AUTOSAR XML (schema 00046)
package /ComponentTypes
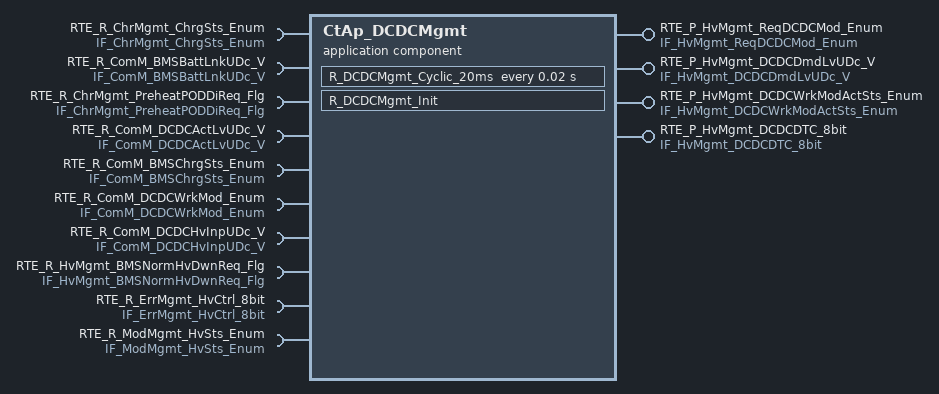
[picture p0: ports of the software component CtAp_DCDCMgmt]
  application sw component type CtAp_DCDCMgmt
    4 x provide port:
      RTE_P_HvMgmt_ReqDCDCMod_Enum: nonqueued-sender-com-spec{data-element=tec_HvMgmt_ReqDCDCMod_Enum, init-value=0}, provided-interface=IF_HvMgmt_ReqDCDCMod_Enum
      RTE_P_HvMgmt_DCDCDmdLvUDc_V: nonqueued-sender-com-spec{data-element=tec_HvMgmt_DCDCDmdLvUDc_V, init-value=0}, provided-interface=IF_HvMgmt_DCDCDmdLvUDc_V
      RTE_P_HvMgmt_DCDCWrkModActSts_Enum: nonqueued-sender-com-spec{data-element=tec_HvMgmt_DCDCWrkModActSts_Enum, init-value=0}, provided-interface=IF_HvMgmt_DCDCWrkModActSts_Enum
      RTE_P_HvMgmt_DCDCDTC_8bit: nonqueued-sender-com-spec{data-element=tec_HvMgmt_DCDCDTC_8bit, init-value=0}, provided-interface=IF_HvMgmt_DCDCDTC_8bit
    10 x require port:
      RTE_R_ChrMgmt_ChrgSts_Enum: nonqueued-receiver-com-spec{data-element=tec_ChrMgmt_ChrgSts_Enum, filter=data-filter-type=ALWAYS, init-value=0}, required-interface=IF_ChrMgmt_ChrgSts_Enum
      RTE_R_ComM_BMSBattLnkUDc_V: nonqueued-receiver-com-spec{data-element=tec_ComM_BMSBattLnkUDc_V, filter=data-filter-type=ALWAYS, init-value=0}, required-interface=IF_ComM_BMSBattLnkUDc_V
      RTE_R_ChrMgmt_PreheatPODDiReq_Flg: nonqueued-receiver-com-spec{data-element=tec_ChrMgmt_PreheatPODDiReq_Flg, filter=data-filter-type=ALWAYS, init-value=0}, required-interface=IF_ChrMgmt_PreheatPODDiReq_Flg
      RTE_R_ComM_DCDCActLvUDc_V: nonqueued-receiver-com-spec{data-element=tec_ComM_DCDCActLvUDc_V, filter=data-filter-type=ALWAYS, init-value=0}, required-interface=IF_ComM_DCDCActLvUDc_V
      RTE_R_ComM_BMSChrgSts_Enum: nonqueued-receiver-com-spec{data-element=tec_ComM_BMSChrgSts_Enum, filter=data-filter-type=ALWAYS, init-value=0}, required-interface=IF_ComM_BMSChrgSts_Enum
      RTE_R_ComM_DCDCWrkMod_Enum: nonqueued-receiver-com-spec{data-element=tec_ComM_DCDCWrkMod_Enum, filter=data-filter-type=ALWAYS, init-value=0}, required-interface=IF_ComM_DCDCWrkMod_Enum
      RTE_R_ComM_DCDCHvInpUDc_V: nonqueued-receiver-com-spec{data-element=tec_ComM_DCDCHvInpUDc_V, filter=data-filter-type=ALWAYS, init-value=0}, required-interface=IF_ComM_DCDCHvInpUDc_V
      RTE_R_HvMgmt_BMSNormHvDwnReq_Flg: nonqueued-receiver-com-spec{data-element=tec_HvMgmt_BMSNormHvDwnReq_Flg, filter=data-filter-type=ALWAYS, init-value=0}, required-interface=IF_HvMgmt_BMSNormHvDwnReq_Flg
      RTE_R_ErrMgmt_HvCtrl_8bit: nonqueued-receiver-com-spec{data-element=tec_ErrMgmt_HvCtrl_8bit, filter=data-filter-type=ALWAYS, init-value=0}, required-interface=IF_ErrMgmt_HvCtrl_8bit
      RTE_R_ModMgmt_HvSts_Enum: nonqueued-receiver-com-spec{data-element=tec_ModMgmt_HvSts_Enum, filter=data-filter-type=ALWAYS, init-value=0}, required-interface=IF_ModMgmt_HvSts_Enum
    behavior CtAp_DCDCMgmt_InternalBehavior
      timing event TMT_R_DCDCMgmt_Cyclic_20ms: start-on-event=R_DCDCMgmt_Cyclic_20ms, period=0.02
      init event CtAp_DCDCMgmt_InitEvent: start-on-event=R_DCDCMgmt_Init
      runnable R_DCDCMgmt_Cyclic_20ms
        data-receive-point-by-arguments:
          10 x access:
            REC_RTE_R_ChrMgmt_ChrgSts_Enum_tec_ChrMgmt_ChrgSts_Enum: accessed-variable=RTE_R_ChrMgmt_ChrgSts_Enum.tec_ChrMgmt_ChrgSts_Enum
            REC_RTE_R_ChrMgmt_PreheatPODDiReq_Flg_tec_ChrMgmt_PreheatPODDiReq_Flg: accessed-variable=RTE_R_ChrMgmt_PreheatPODDiReq_Flg.tec_ChrMgmt_PreheatPODDiReq_Flg
            REC_RTE_R_ComM_BMSBattLnkUDc_V_tec_ComM_BMSBattLnkUDc_V: accessed-variable=RTE_R_ComM_BMSBattLnkUDc_V.tec_ComM_BMSBattLnkUDc_V
            REC_RTE_R_ComM_BMSChrgSts_Enum_tec_ComM_BMSChrgSts_Enum: accessed-variable=RTE_R_ComM_BMSChrgSts_Enum.tec_ComM_BMSChrgSts_Enum
            REC_RTE_R_ComM_DCDCActLvUDc_V_tec_ComM_DCDCActLvUDc_V: accessed-variable=RTE_R_ComM_DCDCActLvUDc_V.tec_ComM_DCDCActLvUDc_V
            REC_RTE_R_ComM_DCDCHvInpUDc_V_tec_ComM_DCDCHvInpUDc_V: accessed-variable=RTE_R_ComM_DCDCHvInpUDc_V.tec_ComM_DCDCHvInpUDc_V
            REC_RTE_R_ComM_DCDCWrkMod_Enum_tec_ComM_DCDCWrkMod_Enum: accessed-variable=RTE_R_ComM_DCDCWrkMod_Enum.tec_ComM_DCDCWrkMod_Enum
            REC_RTE_R_ErrMgmt_HvCtrl_8bit_tec_ErrMgmt_HvCtrl_8bit: accessed-variable=RTE_R_ErrMgmt_HvCtrl_8bit.tec_ErrMgmt_HvCtrl_8bit
            REC_RTE_R_HvMgmt_BMSNormHvDwnReq_Flg_tec_HvMgmt_BMSNormHvDwnReq_Flg: accessed-variable=RTE_R_HvMgmt_BMSNormHvDwnReq_Flg.tec_HvMgmt_BMSNormHvDwnReq_Flg
            REC_RTE_R_ModMgmt_HvSts_Enum_tec_ModMgmt_HvSts_Enum: accessed-variable=RTE_R_ModMgmt_HvSts_Enum.tec_ModMgmt_HvSts_Enum
        data-send-points:
          4 x access:
            SEND_RTE_P_HvMgmt_DCDCDTC_8bit_tec_HvMgmt_DCDCDTC_8bit: accessed-variable=RTE_P_HvMgmt_DCDCDTC_8bit.tec_HvMgmt_DCDCDTC_8bit
            SEND_RTE_P_HvMgmt_DCDCDmdLvUDc_V_tec_HvMgmt_DCDCDmdLvUDc_V: accessed-variable=RTE_P_HvMgmt_DCDCDmdLvUDc_V.tec_HvMgmt_DCDCDmdLvUDc_V
            SEND_RTE_P_HvMgmt_DCDCWrkModActSts_Enum_tec_HvMgmt_DCDCWrkModActSts_Enum: accessed-variable=RTE_P_HvMgmt_DCDCWrkModActSts_Enum.tec_HvMgmt_DCDCWrkModActSts_Enum
            SEND_RTE_P_HvMgmt_ReqDCDCMod_Enum_tec_HvMgmt_ReqDCDCMod_Enum: accessed-variable=RTE_P_HvMgmt_ReqDCDCMod_Enum.tec_HvMgmt_ReqDCDCMod_Enum
      runnable R_DCDCMgmt_Init
  swc implementation CtAp_DCDCMgmt_Implementation: behavior=CtAp_DCDCMgmt_InternalBehavior
    code-descriptors:
      code Default: artifact-descriptors=autosar-engineering-object=category=SWOBJ
